VERSION ""

NS_ :

BS_:

BU_:
    NEO
    MCU
    GTW
    EPAS
    DI
    ESP
    SBW
    STW
	APP
	DAS

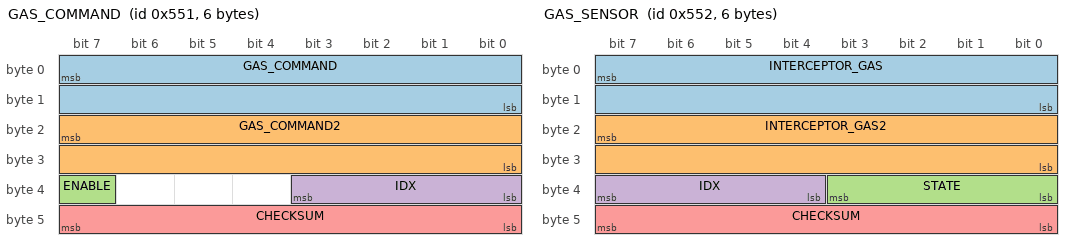
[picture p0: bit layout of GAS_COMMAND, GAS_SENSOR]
BO_ 1361 GAS_COMMAND: 6 EON
 SG_ GAS_COMMAND : 7|16@0+ (0.0507968128,-22.85856576) [0|1] "" INTERCEPTOR
 SG_ GAS_COMMAND2 : 23|16@0+ (0.1015936256,-22.85856576) [0|1] "" INTERCEPTOR
 SG_ ENABLE : 39|1@0+ (1,0) [0|1] "" INTERCEPTOR
 SG_ IDX : 35|4@0+ (1,0) [0|15] "" INTERCEPTOR
 SG_ CHECKSUM : 47|8@0+ (1,0) [0|3] "" INTERCEPTOR

BO_ 1362 GAS_SENSOR: 6 INTERCEPTOR
 SG_ INTERCEPTOR_GAS : 7|16@0+ (0.0507968128,-22.85856576) [0|1] "" EON
 SG_ INTERCEPTOR_GAS2 : 23|16@0+ (0.1015936256,-22.85856576) [0|1] "" EON
 SG_ STATE : 35|4@0+ (1,0) [0|15] "" EON
 SG_ IDX : 39|4@0+ (1,0) [0|15] "" EON
 SG_ CHECKSUM : 47|8@0+ (1,0) [0|3] "" EON

VAL_ 1362 STATE 5 "FAULT_TIMEOUT" 4 "FAULT_STARTUP" 3 "FAULT_SCE" 2 "FAULT_SEND" 1 "FAULT_BAD_CHECKSUM" 0 "NO_FAULT" ;
